# RockChip_RK3588 register map
Vendor: RockChip Electronics Co., Ltd.; Series: RK3588; File version: 0.1
Registers are 32-bit, read-write, no defined reset value unless marked. A register's access mark holds for its fields unless they carry their own. Offsets are from the block's base; [hi:lo] are bit positions; {n}, {i} and the like mark numbered series.

## FIREWALL_DDR
Base 0xFE030000
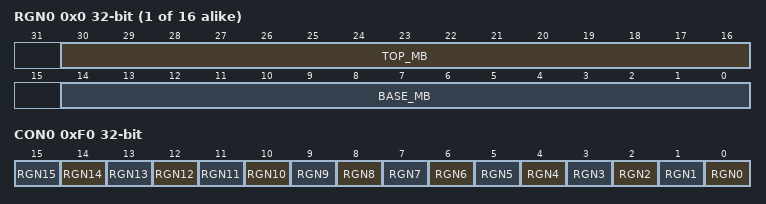
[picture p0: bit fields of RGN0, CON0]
{0x0+4i} RGN{i} (i=0..15)
  [30:16] TOP_MB — Last 1MB
  [14:0] BASE_MB — First 1MB
{0x40+4i} MST{i} (i=0..41)
0xF0 CON0
  [all] fields
    1=ENABLE; 0=DISABLE
  [n] RGN{n} (n=0..15)

## FIREWALL_DSUDDR
Base 0xFE010000
Registers as FIREWALL_DDR, without MST{n} (n=2..41), CON0; these are added or differ:
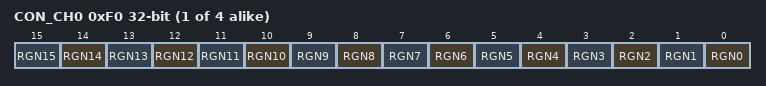
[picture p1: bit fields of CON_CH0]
{0xF0+4i} CON_CH{i} (i=0..3)
  [all] fields
    1=ENABLE; 0=DISABLE
  [n] RGN{n} (n=0..15)

## FIREWALL_SYSMEM
Base 0xFE038000
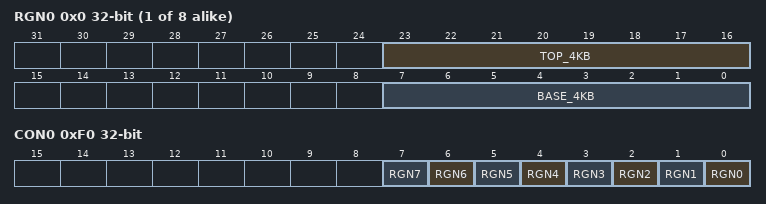
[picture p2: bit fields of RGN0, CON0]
{0x0+4i} RGN{i} (i=0..7)
  [23:16] TOP_4KB — Last 4KB
  [7:0] BASE_4KB — First 4KB
{0x40+4i} MST{i} (i=0..42)
0xF0 CON0
  [all] fields
    1=ENABLE; 0=DISABLE
  [n] RGN{n} (n=0..7)

## GRF_BIGCORE0
Base 0xFD590000
Same registers: GRF_BIGCORE1 0xFD592000
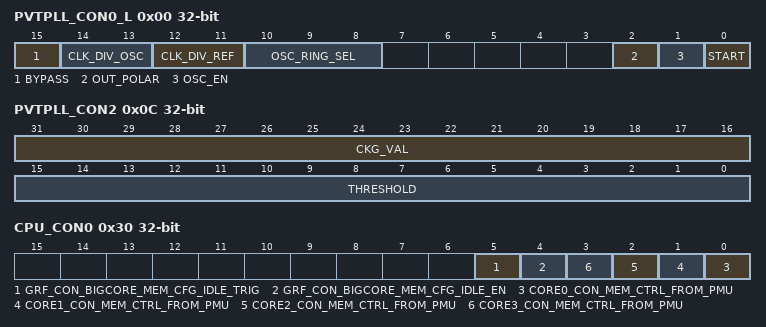
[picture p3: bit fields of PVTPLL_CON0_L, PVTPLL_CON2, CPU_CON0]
0x00 PVTPLL_CON0_L — PVTPLL Control Register 0 Low
  [15] BYPASS
    0=SUPPORT (Support glitch-free frequency conversion.); 1=NOT_SUPPORT
  [14:13] CLK_DIV_OSC — Frequency division factor for osc_clk.
  [12:11] CLK_DIV_REF — Frequency division factor for ref_clk.
  [10:8] OSC_RING_SEL — Oscillator ring channel select.
  [2] OUT_POLAR
    0=OUT_1 (Out=1 when need to increase volt.); 1=OUT_0 (Out=0 when need to increase volt.)
  [1] OSC_EN — Oscillator ring enable.
    0=DISABLE; 1=ENABLE
  [0] START
    1=START (PVTPLL monitor start.)
0x04 PVTPLL_CON0_H — PVTPLL Control Register 0 High
  [5:0] RING_LENGTH_SEL — Oscillator ring inverter length select.
0x08 PVTPLL_CON1 — PVTPLL Control Register 1
  [31:0] CAL_CNT — Target frequency value.
0x0C PVTPLL_CON2 — PVTPLL Control Register 2
  [31:16] CKG_VAL — Clock gating interval control count value.
  [15:0] THRESHOLD — Count difference threshold value.
0x10 PVTPLL_CON3 — PVTPLL Control Register 3
  [31:0] REF_CNT — Frequency measurement period setting value.
0x20 MEM_CFG_HSSPRF_L — Memory Configuration Register For HSSPRF Low
  [15:0] GRF_BIGCORE_MEM_CFG_HSSPRF_L — bit 0: TEST1 bit 1: TEST_RNM bit 4~2: RM bit 5: WMD bit 7: LS bit 13~12: RA
0x28 MEM_CFG_HSDPRF_L — Memory Configuration Register For HSDPRF
  [15:0] GRF_BIGCORE_MEM_CFG_HSDPRF_L — bit 0: TEST1A bit 1: TEST_RNMA bit 5~2: RMA bit 6: WMDA bit 8: LS bit 14~13: RA
0x2C MEM_CFG_HSDPRF_H — Memory Configuration Register For HSSPRF High
  [15:0] GRF_BIGCORE_MEM_CFG_HSDPRF_H — bit 1: TEST1B bit 5~2: RMB
0x30 CPU_CON0 — CPU Control Register 0
  [5] GRF_CON_BIGCORE_MEM_CFG_IDLE_TRIG — A 0 to 1 trigger of grf_con_bigcore_mem_cfg_idle_trig will cause a mem_cfg change when grf_con_bigcore_mem_cfg_idle_en equals to 1.
  [4] GRF_CON_BIGCORE_MEM_CFG_IDLE_EN
    0=SW_IMMEDIATELY (Mem_cfg is changed by software immediately); 1=ALL_WFI (Mem_cfg is changed when all cpu in wfi)
  [n] CORE{n}_CON_MEM_CTRL_FROM_PMU (n=0..3)
    0=GRF (Mem_cfg is driven by grf); 1=PMU (Mem_cfg is driven by pmu)

## GRF_CENTER
Base 0xFD59E000
0x00 SOC_CON0 — CENTER GRF Control Register 0
  [18:0] MEM_CFG_UHDPDPRF_DMA2DDR_I — bit 0: TEST1 bit 1: TEST_RNM bit 4~2: RM bit 5: WMDA bit 7: LS
0x04 SOC_CON1 — CENTER GRF Control Register 1
  [15:0] MEM_CFG_HDSPRA_SHRM_I — bit 0: TEST1 bit 1: TEST_RNM bit 4~2: RM bit 5: WMD bit 7: LS bit 11~10: WPULSE bit 13~12: RA
0x08 SOC_CON2 — CENTER GRF Control Register 2
  [18:0] MEM_CFG_UHDPDPRF_INTERCONNECT_I — bit 0: TEST1 bit 1: TEST_RNM bit 4~2: RM bit 5: WMDA bit 7: LS
0x0C SOC_CON3 — CENTER GRF Control Register 3
  [15:0] MEM_CFG_HDSPRF_DDRTCM_I — bit 0: TEST1 bit 1: TEST_RNM bit 4~2: RM bit 5: WMDA bit 7: LS
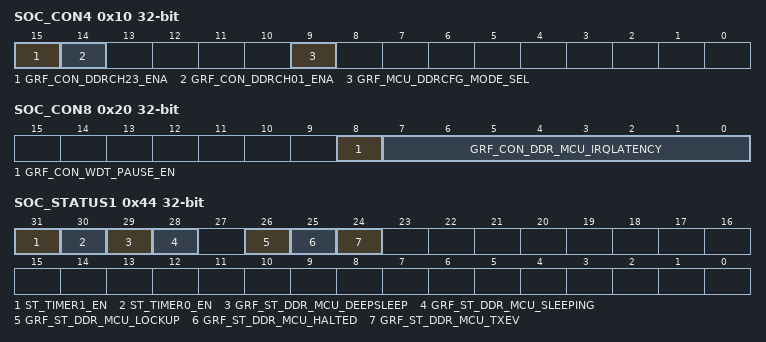
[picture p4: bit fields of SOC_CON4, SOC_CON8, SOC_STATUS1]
0x10 SOC_CON4 — CENTER GRF Control Register 4
  [15] GRF_CON_DDRCH23_ENA
    1=ENABLE (Enable simultaneously configure ddr ch2 and ddr ch3 function.); 0=DISABLE
  [14] GRF_CON_DDRCH01_ENA
    1=ENABLE (Enable simultaneously configure ddr ch0 and ddr ch1 function.); 0=DISABLE
  [9] GRF_MCU_DDRCFG_MODE_SEL
    1=ENABLE (Enable mcu configure ddr mode.); 0=DISABLE
0x1C SOC_CON7 — CENTER GRF Control Register 7
  [0] GRF_CON_DDR_MCU_STCALIB
0x20 SOC_CON8 — CENTER GRF Control Register 8
  [8] GRF_CON_WDT_PAUSE_EN — Center wdt pause enable. Used to freeze the watchdog counter during pause mode.
    1=ACTIVE
  [7:0] GRF_CON_DDR_MCU_IRQLATENCY — Irqlatency specifies the minimum number of cycles between an interrupt that becomes pended in the NVIC, and the vector fetch for that interrupt being issued on the AHB-Lite interface.
0x44 SOC_STATUS1 — CENTER GRF Status Register 1
  [31] ST_TIMER1_EN ro — System timer 1 enable status.
    1=ENABLED; 0=DISABLED
  [30] ST_TIMER0_EN ro — System timer 0 enable status.
    1=ENABLED; 0=DISABLED
  [29] GRF_ST_DDR_MCU_DEEPSLEEP ro — Active only when SLEEPING is HIGH. Indicates that the SLEEPDEEP bit in the NVIC is set to 1.
  [28] GRF_ST_DDR_MCU_SLEEPING ro — Indicates the processor is idle, waiting for an interrupt on either the IRQ, NMI, or internal SysTick, or HIGH level on RXEV.
  [26] GRF_ST_DDR_MCU_LOCKUP ro — Indicates that the processor is in the architected lock-up state, as the result of an unrecoverable exception.
  [25] GRF_ST_DDR_MCU_HALTED ro — Indicates that the processor is in debug state. HALTED remains asserted for as long as the processor remains in debug state.
  [24] GRF_ST_DDR_MCU_TXEV ro — A single SCLK cycle HIGH level is generated on this output every time an SEV instruction is executed.
